AUTOSAR XML (schema 00044)
package /ComponentTypes
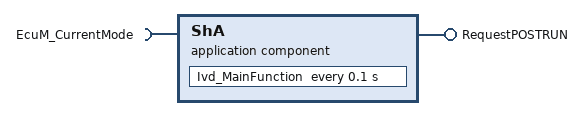
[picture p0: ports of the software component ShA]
  application sw component type ShA
    provide port RequestPOSTRUN: nonqueued-sender-com-spec{data-element=Request, init-value=1}, provided-interface=RequestPOSTRUN
    require port EcuM_CurrentMode: mode-switch-receiver-com-spec=currentMode, required-interface=EcuM_CurrentMode
    behavior ShA_InternalBehavior: data-type-mapping=DTMS_ShA
      swc mode switch event MST_Runnable_0: start-on-event=Ivd_CurrentMode_PostRun, activation=ON-ENTRY, mode=EcuM_CurrentMode.currentMode.POST_RUN
      swc mode switch event MST_Ivd_CurrentMode_Run_0: start-on-event=Ivd_CurrentMode_Run, activation=ON-ENTRY, mode=EcuM_CurrentMode.currentMode.RUN
      init event ShA_InitEvent: start-on-event=Ivd_Init
      timing event TMT_Ivd_MainFunction: start-on-event=Ivd_MainFunction, period=0.1
      4 x runnable:
        Ivd_CurrentMode_PostRun
          data-send-points:
            access SEND_RequestPOSTRUN_Request: accessed-variable=RequestPOSTRUN.Request
        Ivd_CurrentMode_Run
          data-send-points:
            access SEND_RequestPOSTRUN_Request: accessed-variable=RequestPOSTRUN.Request
        Ivd_Init
          data-send-points:
            access SEND_RequestPOSTRUN_Request: accessed-variable=RequestPOSTRUN.Request
        Ivd_MainFunction
          data-send-points:
            access SEND_RequestPOSTRUN_Request: accessed-variable=RequestPOSTRUN.Request
  swc implementation ShA_Implementation: vendor-id=75, behavior=ShA_InternalBehavior
    code-descriptors:
      code Default: artifact-descriptors=autosar-engineering-object=category=SWSRC
    resource consumption ResourceConsumption
      memory section CODE: sw-addrmethod=CODE
      memory section VAR_INIT_UNSPECIFIED: alignment=UNSPECIFIED, sw-addrmethod=VAR_INIT
